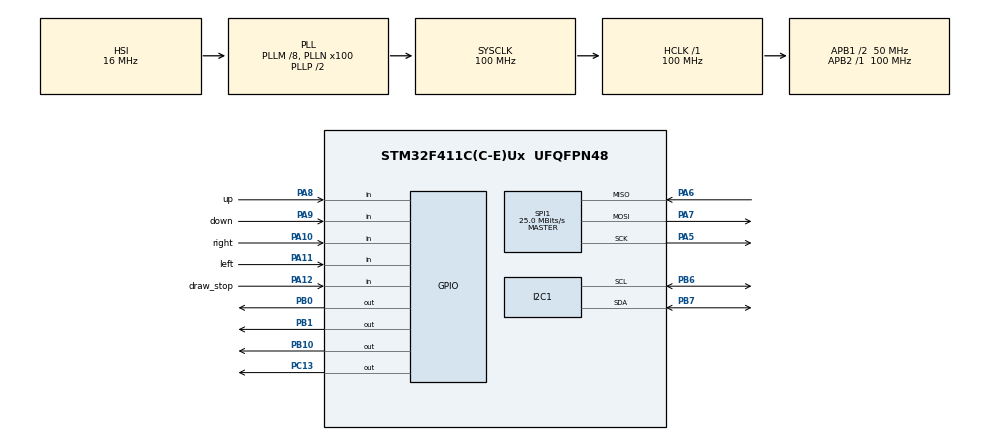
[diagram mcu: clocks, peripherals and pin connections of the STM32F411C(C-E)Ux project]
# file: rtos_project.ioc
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Dma.Request0=SPI1_TX
Dma.SPI1_TX.0.Direction=DMA_MEMORY_TO_PERIPH
Dma.SPI1_TX.0.FIFOMode=DMA_FIFOMODE_DISABLE
Dma.SPI1_TX.0.Instance=DMA2_Stream2
Dma.SPI1_TX.0.MemDataAlignment=DMA_MDATAALIGN_BYTE
Dma.SPI1_TX.0.MemInc=DMA_MINC_ENABLE
Dma.SPI1_TX.0.Mode=DMA_NORMAL
Dma.SPI1_TX.0.PeriphDataAlignment=DMA_PDATAALIGN_BYTE
Dma.SPI1_TX.0.PeriphInc=DMA_PINC_DISABLE
Dma.SPI1_TX.0.Priority=DMA_PRIORITY_LOW
FREERTOS.BinarySemaphores01=disp_semaphore,Dynamic,NULL
FREERTOS.Tasks01=defaultTask,0,128,StartDefaultTask,Default,NULL,Dynamic,NULL,NULL;baca_sht,-2,512,start_baca_sht,Default,NULL,Dynamic,NULL,NULL;display,1,1024,start_display,Default,NULL,Dynamic,NULL,NULL;input_poll,0,256,start_input_poll,Default,NULL,Dynamic,NULL,NULL;game_master,-1,1024,start_game_master,Default,NULL,Dynamic,NULL,NULL
Mcu.Family=STM32F4
Mcu.Name=STM32F411C(C-E)Ux
Mcu.Package=UFQFPN48
NVIC.DMA2_Stream2_IRQn=true\:5\:0\:false\:false\:true\:true\:false\:true\:true
NVIC.PriorityGroup=NVIC_PRIORITYGROUP_4
NVIC.TIM1_UP_TIM10_IRQn=true\:15\:0\:false\:false\:true\:false\:false\:true\:true
NVIC.TimeBase=TIM1_UP_TIM10_IRQn
NVIC.TimeBaseIP=TIM1
PA10.GPIO_Label=right
PA10.GPIO_PuPd=GPIO_PULLDOWN
PA10.Signal=GPIO_Input
PA11.GPIO_Label=left
PA11.GPIO_PuPd=GPIO_PULLDOWN
PA11.Signal=GPIO_Input
PA12.GPIO_Label=draw_stop
PA12.GPIO_PuPd=GPIO_PULLDOWN
PA12.Signal=GPIO_Input
PA13.Mode=Serial_Wire
PA13.Signal=SYS_JTMS-SWDIO
PA14.Mode=Serial_Wire
PA14.Signal=SYS_JTCK-SWCLK
PA5.Mode=Full_Duplex_Master
PA5.Signal=SPI1_SCK
PA6.Mode=Full_Duplex_Master
PA6.Signal=SPI1_MISO
PA7.Mode=Full_Duplex_Master
PA7.Signal=SPI1_MOSI
PA8.GPIO_Label=up
PA8.GPIO_PuPd=GPIO_PULLDOWN
PA8.Signal=GPIO_Input
PA9.GPIO_Label=down
PA9.GPIO_PuPd=GPIO_PULLDOWN
PA9.Signal=GPIO_Input
PB0.Signal=GPIO_Output
PB1.Signal=GPIO_Output
PB10.Signal=GPIO_Output
PB6.Mode=I2C
PB6.Signal=I2C1_SCL
PB7.Mode=I2C
PB7.Signal=I2C1_SDA
PC13-ANTI_TAMP.Signal=GPIO_Output
PC14-OSC32_IN.Mode=LSE-External-Oscillator
PC14-OSC32_IN.Signal=RCC_OSC32_IN
PC15-OSC32_OUT.Mode=LSE-External-Oscillator
PC15-OSC32_OUT.Signal=RCC_OSC32_OUT
PH0\ -\ OSC_IN.Mode=HSE-External-Oscillator
PH0\ -\ OSC_IN.Signal=RCC_OSC_IN
PH1\ -\ OSC_OUT.Mode=HSE-External-Oscillator
PH1\ -\ OSC_OUT.Signal=RCC_OSC_OUT
ProjectManager.HeapSize=0x200
ProjectManager.StackSize=0x400
ProjectManager.TargetToolchain=STM32CubeIDE
RCC.48MHZClocksFreq_Value=50000000
RCC.AHBFreq_Value=100000000
RCC.APB1CLKDivider=RCC_HCLK_DIV2
RCC.APB1Freq_Value=50000000
RCC.APB1TimFreq_Value=100000000
RCC.APB2Freq_Value=100000000
RCC.APB2TimFreq_Value=100000000
RCC.CortexFreq_Value=100000000
RCC.HCLKFreq_Value=100000000
RCC.HSE_VALUE=25000000
RCC.HSI_VALUE=16000000
RCC.PLLM=8
RCC.PLLN=100
RCC.SYSCLKFreq_VALUE=100000000
RCC.SYSCLKSource=RCC_SYSCLKSOURCE_PLLCLK
RCC.VCOOutputFreq_Value=200000000
RTC.Date=22
RTC.Month=RTC_MONTH_SEPTEMBER
RTC.WeekDay=RTC_WEEKDAY_SUNDAY
RTC.Year=24
SPI1.BaudRatePrescaler=SPI_BAUDRATEPRESCALER_4
SPI1.CalculateBaudRate=25.0 MBits/s
SPI1.Direction=SPI_DIRECTION_2LINES
SPI1.Mode=SPI_MODE_MASTER
SPI1.VirtualType=VM_MASTER
VP_FREERTOS_VS_CMSIS_V1.Mode=CMSIS_V1
VP_RTC_VS_RTC_Activate.Mode=RTC_Enabled
VP_RTC_VS_RTC_Calendar.Mode=RTC_Calendar
VP_SYS_VS_tim1.Mode=TIM1
board=custom

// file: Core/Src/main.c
/* USER CODE BEGIN Header */
/**
  ******************************************************************************
  * @file           : main.c
  * @brief          : Main program body
  ******************************************************************************
  * @attention
  *
  * Copyright (c) 2024 STMicroelectronics.
  * All rights reserved.
  *
  * This software is licensed under terms that can be found in the LICENSE file
  * in the root directory of this software component.
  * If no LICENSE file comes with this software, it is provided AS-IS.
  *
  ******************************************************************************
  */
/* USER CODE END Header */
#include "main.h"
#include "cmsis_os.h"

/* USER CODE BEGIN Includes */
#include "stm32f4xx_hal.h"
#include <string.h>
#include <stdarg.h>
#include <stdio.h>
#include <stdbool.h>
#include <stdlib.h>
#include "ili9341.h"
#include "ili9341_touch.h"
#include "fonts.h"
#include "testimg.h"
#include "sht2x_for_stm32_hal.h"
/* USER CODE END Includes */

/* USER CODE BEGIN PD */
#define INCREMENT 1
#define PADDLE_WIDTH 5
#define PADDLE_HEIGHT 30
#define PADDLE_SPEED 4
#define BALL_SIZE 3
#define BALL_VELY 5
#define BALL_VELX 5
/* USER CODE END PD */

I2C_HandleTypeDef hi2c1;

RTC_HandleTypeDef hrtc;

SPI_HandleTypeDef hspi1;
DMA_HandleTypeDef hdma_spi1_tx;

osThreadId defaultTaskHandle;
osThreadId baca_shtHandle;
osThreadId displayHandle;
osThreadId input_pollHandle;
osThreadId game_masterHandle;
osSemaphoreId disp_semaphoreHandle;
/* USER CODE BEGIN PV */
static float temp=0;
static float hum;
char str1[40];
char str2[40];
char date[150];
char score_left[10];
char score_right[10];
int scoreL;
int scoreR;
float buffer[10]; // Moving Average Filter
float buffer_hum[10];
float filtered_temp;
float filtered_hum;
int x,y;
int oldx,oldy;
int ouserx,ousery;
int obotx,oboty;
int random_number;
//bool isDrawing;
bool playerEnable;

typedef struct {
	int x;
	int y;
	int width;
	int height;
	int speed;
} paddle;

typedef struct {
	int x;
	int y;
	int velx;
	int vely;
	int rad;
} ball;

paddle user;
paddle bot;
ball bola;

// GAMBAR PETIR
const uint16_t test_img_50x50[][50] = {
{0x0000,0x0000,0x0000,0x0000,0x0000,0x0000,0x0000,0x0000,0x0000,0x0000,0x0000,0x0000,0x0000,0x0000,0x0000,0x0000,0x0000,0x0000,0x0000,0x0000,0x0000,0x0000,0x0000,0x0000,0x0000,0x0000,0x0000,0x0000,0x0000,0x0000,0x0000,0x0000,0x0000,0x0000,0x0000,0x0000,0x0000,0x0000,0x0000,0x0000,0x0000,0x0000,0x0000,0x0000,0x0000,0x0000,0x0000,0x0000,0x0000,0x0000,},
{0x0000,0x0000,0x0000,0x0000,0x0000,0x0000,0x0000,0x0000,0x0000,0x0000,0x0000,0x0000,0x0000,0x0000,0x0000,0x0000,0x0000,0x0000,0x0000,0x0000,0x0000,0x0000,0x0000,0x0000,0x0000,0x0000,0x0000,0x0000,0x0000,0x0000,0x0000,0x0000,0x0000,0x0000,0x0000,0x0000,0x0000,0x0000,0x0000,0x0000,0x0000,0x0000,0x0000,0x0000,0x0000,0x0000,0x0000,0x0000,0x0000,0x0000,},
{0x0000,0x0000,0x0000,0x0000,0x0000,0x0000,0x0000,0x0000,0x0000,0x0000,0x0000,0x0000,0x0000,0x0000,0x0000,0x0000,0x0000,0x0000,0x0000,0x0000,0x0000,0x0000,0x0000,0x0000,0x0000,0x0000,0x0000,0x0000,0x0000,0x0000,0x0000,0x0000,0x0000,0x0000,0x0000,0x0000,0x0000,0x0000,0x0000,0x0000,0x0000,0x0000,0x0000,0x0000,0x0000,0x0000,0x0000,0x0000,0x0000,0x0000,},
{0x0000,0x0000,0x0000,0x0000,0x0000,0x0000,0x0000,0x0000,0x0000,0x0000,0x0000,0x0000,0x0000,0x0000,0x0000,0x0000,0x0000,0x0000,0x0000,0x0000,0x0000,0x4529,0xEB5A,0xE739,0x4108,0x0000,0x0000,0x0000,0x0000,0x0000,0x0000,0x0000,0x0000,0x0000,0x0000,0x0000,0x0000,0x0000,0x0000,0x0000,0x0000,0x0000,0x0000,0x0000,0x0000,0x0000,0x0000,0x0000,0x0000,0x0000,},
{0x0000,0x0000,0x0000,0x0000,0x0000,0x0000,0x0000,0x0000,0x0000,0x0000,0x0000,0x0000,0x0000,0x0000,0x0000,0x0000,0x0000,0x0000,0x0000,0x0000,0x4529,0x38C6,0x9EF7,0x3CE7,0xEB5A,0x4108,0x0000,0x0000,0x0000,0x0000,0x0000,0x0000,0x0000,0x0000,0x0000,0x0000,0x0000,0x0000,0x0000,0x0000,0x0000,0x0000,0x0000,0x0000,0x0000,0x0000,0x0000,0x0000,0x0000,0x0000,},
{0x0000,0x0000,0x0000,0x0000,0x0000,0x0000,0x0000,0x0000,0x0000,0x0000,0x0000,0x0000,0x0000,0x0000,0x0000,0x0000,0x0000,0x0000,0x0000,0x0000,0xEF7B,0xFFFF,0xFFFF,0xFFFF,0xD7BD,0x0421,0x0000,0x0000,0x0000,0x0000,0x0000,0x0000,0x0000,0x0000,0x0000,0x0000,0x0000,0x0000,0x0000,0x0000,0x0000,0x0000,0x0000,0x0000,0x0000,0x0000,0x0000,0x0000,0x0000,0x0000,},
{0x0000,0x0000,0x0000,0x0000,0x0000,0x0000,0x0000,0x0000,0x0000,0x0000,0x0000,0x0000,0x0000,0x0000,0x0000,0x0000,0x0000,0x0000,0x0000,0x0000,0x18C6,0xFFFF,0xFFFF,0xFFFF,0xBAD6,0x2421,0x0000,0x0000,0x0000,0x0000,0x0000,0x0000,0x0000,0x0000,0x0000,0x0000,0x0000,0x0000,0x0000,0x0000,0x0000,0x0000,0x0000,0x0000,0x0000,0x0000,0x0000,0x0000,0x0000,0x0000,},
{0x0000,0x0000,0x0000,0x0000,0x0000,0x0000,0x0000,0x0000,0x0000,0x0000,0x0000,0x0000,0x0000,0x0000,0x0000,0x0000,0x0000,0x0000,0x0000,0x694A,0xDFFF,0xFFFF,0xFFFF,0xFFFF,0x38C6,0x6108,0x0000,0x0000,0x0000,0x0000,0x0000,0x0000,0x0000,0x0000,0x0000,0x0000,0x0000,0x0000,0x0000,0x0000,0x0000,0x0000,0x0000,0x0000,0x0000,0x0000,0x0000,0x0000,0x0000,0x0000,},
{0x0000,0x0000,0x0000,0x0000,0x0000,0x0000,0x0000,0x0000,0x0000,0x0000,0x0000,0x0000,0x0000,0x0000,0x0000,0x0000,0x0000,0x0000,0x0000,0xF7BD,0xFFFF,0xFFFF,0xFFFF,0xFFFF,0xEF7B,0x0000,0x0000,0x0000,0x0000,0x0000,0x0000,0x0000,0x0000,0x0000,0x0000,0x0000,0x0000,0x0000,0x0000,0x0000,0x0000,0x0000,0x0000,0x0000,0x0000,0x0000,0x0000,0x0000,0x0000,0x0000,},
{0x0000,0x0000,0x0000,0x0000,0x0000,0x0000,0x0000,0x0000,0x0000,0x0000,0x0000,0x0000,0x0000,0x0000,0x0000,0x0000,0x0000,0x0000,0xAA52,0xBEF7,0xFFFF,0xFFFF,0xFFFF,0x9EF7,0xA631,0x0000,0x0000,0x0000,0x0000,0x0000,0x0000,0x0000,0x0000,0x0000,0x0000,0x0000,0x0000,0x0000,0x0000,0x0000,0x0000,0x0000,0x0000,0x0000,0x0000,0x0000,0x0000,0x0000,0x0000,0x0000,},
{0x0000,0x0000,0x0000,0x0000,0x0000,0x0000,0x0000,0x0000,0x0000,0x0000,0x0000,0x0000,0x0000,0x0000,0x0000,0x0000,0x0000,0x0421,0xDBDE,0xFFFF,0xFFFF,0xFFFF,0xFFFF,0xB6B5,0x6108,0x0000,0x0000,0x0000,0x0000,0x0000,0x0000,0x0000,0x0000,0x0000,0x0000,0x0000,0x0000,0x0000,0x0000,0x0000,0x0000,0x0000,0x0000,0x0000,0x0000,0x0000,0x0000,0x0000,0x0000,0x0000,},
{0x0000,0x0000,0x0000,0x0000,0x0000,0x0000,0x0000,0x0000,0x0000,0x0000,0x0000,0x0000,0x0000,0x0000,0x0000,0x0000,0x0000,0xD39C,0xFFFF,0xFFFF,0xFFFF,0xFFFF,0x7DEF,0x2842,0x0000,0x0000,0x0000,0x0000,0x0000,0x0000,0x0000,0x0000,0x0000,0x0000,0x0000,0x0000,0x0000,0x0000,0x0000,0x0000,0x0000,0x0000,0x0000,0x0000,0x0000,0x0000,0x0000,0x0000,0x0000,0x0000,},
{0x0000,0x0000,0x0000,0x0000,0x0000,0x0000,0x0000,0x0000,0x0000,0x0000,0x0000,0x0000,0x0000,0x0000,0x0000,0x0000,0xE739,0x9EF7,0xFFFF,0xFFFF,0xFFFF,0xFFFF,0xEF7B,0x0000,0x0000,0x0000,0x0000,0x0000,0x0000,0x0000,0x0000,0x0000,0x0000,0x0000,0x0000,0x0000,0x0000,0x0000,0x0000,0x0000,0x0000,0x0000,0x0000,0x0000,0x0000,0x0000,0x0000,0x0000,0x0000,0x0000,},
{0x0000,0x0000,0x0000,0x0000,0x0000,0x0000,0x0000,0x0000,0x0000,0x0000,0x0000,0x0000,0x0000,0x0000,0x0000,0x0000,0xF39C,0xFFFF,0xFFFF,0xFFFF,0xFFFF,0x3CE7,0x0421,0x0000,0x0000,0x0000,0x0000,0x0000,0x0000,0x0000,0x0000,0x0000,0x0000,0x0000,0x0000,0x0000,0x0000,0x0000,0x0000,0x0000,0x0000,0x0000,0x0000,0x0000,0x0000,0x0000,0x0000,0x0000,0x0000,0x0000,},
{0x0000,0x0000,0x0000,0x0000,0x0000,0x0000,0x0000,0x0000,0x0000,0x0000,0x0000,0x0000,0x0000,0x0000,0x0000,0x4529,0x3CE7,0xFFFF,0xFFFF,0xFFFF,0xFFFF,0x718C,0x0000,0x0000,0x0000,0x0000,0x0000,0x0000,0x0000,0x0000,0x0000,0x0000,0x0000,0x0000,0x0000,0x0000,0x0000,0x0000,0x0000,0x0000,0x0000,0x0000,0x0000,0x0000,0x0000,0x0000,0x0000,0x0000,0x0000,0x0000,},
{0x0000,0x0000,0x0000,0x0000,0x0000,0x0000,0x0000,0x0000,0x0000,0x0000,0x0000,0x0000,0x0000,0x0000,0x0000,0x518C,0xFFFF,0xFFFF,0xFFFF,0xFFFF,0x3CE7,0x0421,0x0000,0x0000,0x0000,0x0000,0x0000,0x0000,0x0000,0x0000,0x0000,0x0000,0x0000,0x0000,0x0000,0x0000,0x0000,0x0000,0x0000,0x0000,0x0000,0x0000,0x0000,0x0000,0x0000,0x0000,0x0000,0x0000,0x0000,0x0000,},
{0x0000,0x0000,0x0000,0x0000,0x0000,0x0000,0x0000,0x0000,0x0000,0x0000,0x0000,0x0000,0x0000,0x0000,0x4529,0x3CE7,0xFFFF,0xFFFF,0xFFFF,0xFFFF,0x9294,0x0000,0x0000,0x0000,0x0000,0x0000,0x0000,0x0000,0x0000,0x0000,0x0000,0x0000,0x0000,0x0000,0x0000,0x0000,0x0000,0x0000,0x0000,0x0000,0x0000,0x0000,0x0000,0x0000,0x0000,0x0000,0x0000,0x0000,0x0000,0x0000,},
{0x0000,0x0000,0x0000,0x0000,0x0000,0x0000,0x0000,0x0000,0x0000,0x0000,0x0000,0x0000,0x0000,0x0000,0xF39C,0xFFFF,0xFFFF,0xFFFF,0xFFFF,0x1CE7,0x0421,0x0000,0x0000,0x0000,0x0000,0x0000,0x0000,0x0000,0x0000,0x0000,0x0000,0x0000,0x0000,0x0000,0x0000,0x0000,0x0000,0x0000,0x0000,0x0000,0x0000,0x0000,0x0000,0x0000,0x0000,0x0000,0x0000,0x0000,0x0000,0x0000,},
{0x0000,0x0000,0x0000,0x0000,0x0000,0x0000,0x0000,0x0000,0x0000,0x0000,0x0000,0x0000,0x0000,0xE739,0xBEF7,0xFFFF,0xFFFF,0xFFFF,0xFFFF,0x0C63,0x0000,0x0000,0x0000,0x0000,0x0000,0x0000,0x0000,0x0000,0x0000,0x0000,0x0000,0x0000,0x0000,0x0000,0x0000,0x0000,0x0000,0x0000,0x0000,0x0000,0x0000,0x0000,0x0000,0x0000,0x0000,0x0000,0x0000,0x0000,0x0000,0x0000,},
{0x0000,0x0000,0x0000,0x0000,0x0000,0x0000,0x0000,0x0000,0x0000,0x0000,0x0000,0x0000,0x0000,0x75AD,0xFFFF,0xFFFF,0xFFFF,0xFFFF,0xB6B5,0x0000,0x0000,0x0000,0x0000,0x0000,0x0000,0x0000,0x0000,0x0000,0x0000,0x0000,0x0000,0x0000,0x0000,0x0000,0x0000,0x0000,0x0000,0x0000,0x0000,0x0000,0x0000,0x0000,0x0000,0x0000,0x0000,0x0000,0x0000,0x0000,0x0000,0x0000,},
{0x0000,0x0000,0x0000,0x0000,0x0000,0x0000,0x0000,0x0000,0x0000,0x0000,0x0000,0x0000,0xE739,0xBEF7,0xFFFF,0xFFFF,0xFFFF,0xBEF7,0xE739,0x0000,0x0000,0x0000,0x0000,0x0000,0x0000,0x0000,0x0000,0x0000,0x0000,0x0000,0x0000,0x0000,0x0000,0x0000,0x0000,0x0000,0x0000,0x0000,0x0000,0x0000,0x0000,0x0000,0x0000,0x0000,0x0000,0x0000,0x0000,0x0000,0x0000,0x0000,},
{0x0000,0x0000,0x0000,0x0000,0x0000,0x0000,0x0000,0x0000,0x0000,0x0000,0x0000,0x0000,0x34A5,0xFFFF,0xFFFF,0xFFFF,0xFFFF,0xB294,0x0000,0x0000,0x0000,0x0000,0x0000,0x0000,0x0000,0x0000,0x0000,0x0000,0x0000,0x0000,0x0000,0x0000,0x0000,0x0000,0x0000,0x0000,0x0000,0x0000,0x0000,0x0000,0x0000,0x0000,0x0000,0x0000,0x0000,0x0000,0x0000,0x0000,0x0000,0x0000,},
{0x0000,0x0000,0x0000,0x0000,0x0000,0x0000,0x0000,0x0000,0x0000,0x0000,0x0000,0x6108,0xFBDE,0xFFFF,0xFFFF,0xFFFF,0x9EF7,0xA631,0x0000,0x0000,0x0000,0x0000,0x0000,0x0000,0x0000,0x0000,0x6108,0x2421,0x6529,0x6529,0xE739,0x0C63,0xCB5A,0x0421,0x0000,0x0000,0x0000,0x0000,0x0000,0x0000,0x0000,0x0000,0x0000,0x0000,0x0000,0x0000,0x0000,0x0000,0x0000,0x0000,},
{0x0000,0x0000,0x0000,0x0000,0x0000,0x0000,0x0000,0x0000,0x0000,0x0000,0x0000,0x14A5,0xFFFF,0xFFFF,0xFFFF,0xFFFF,0xFBDE,0x8E73,0x6D6B,0x6D6B,0x6D6B,0xCF7B,0xB294,0xF39C,0x34A5,0xB6B5,0x59CE,0x9AD6,0xFBDE,0x1CE7,0x9EF7,0xDFFF,0x9EF7,0x75AD,0x0421,0x0000,0x0000,0x0000,0x0000,0x0000,0x0000,0x0000,0x0000,0x0000,0x0000,0x0000,0x0000,0x0000,0x0000,0x0000,},
{0x0000,0x0000,0x0000,0x0000,0x0000,0x0000,0x0000,0x0000,0x0000,0x0000,0x4D6B,0xFFFF,0xFFFF,0xFFFF,0xFFFF,0xFFFF,0xDFFF,0xDFFF,0xDFFF,0xDFFF,0xDFFF,0xFFFF,0xFFFF,0xFFFF,0xFFFF,0xFFFF,0xFFFF,0xFFFF,0xFFFF,0xFFFF,0xFFFF,0xFFFF,0xFFFF,0xFFFF,0x2C63,0x0000,0x0000,0x0000,0x0000,0x0000,0x0000,0x0000,0x0000,0x0000,0x0000,0x0000,0x0000,0x0000,0x0000,0x0000,},
{0x0000,0x0000,0x0000,0x0000,0x0000,0x0000,0x0000,0x0000,0x0000,0x6108,0xBAD6,0xFFFF,0xFFFF,0xFFFF,0xFFFF,0xFFFF,0xFFFF,0xFFFF,0xFFFF,0xFFFF,0xFFFF,0xFFFF,0xFFFF,0xFFFF,0xFFFF,0xFFFF,0xFFFF,0xFFFF,0xFFFF,0xFFFF,0xFFFF,0xFFFF,0xFFFF,0xFFFF,0xAE73,0x0000,0x0000,0x0000,0x0000,0x0000,0x0000,0x0000,0x0000,0x0000,0x0000,0x0000,0x0000,0x0000,0x0000,0x0000,},
{0x0000,0x0000,0x0000,0x0000,0x0000,0x0000,0x0000,0x0000,0x0000,0xA210,0x9AD6,0xFFFF,0xFFFF,0xFFFF,0xFFFF,0xFFFF,0xFFFF,0xFFFF,0xFFFF,0xFFFF,0xFFFF,0xFFFF,0xFFFF,0xFFFF,0xFFFF,0xFFFF,0xFFFF,0xFFFF,0xFFFF,0xFFFF,0xFFFF,0xFFFF,0xFFFF,0x9EF7,0xE739,0x0000,0x0000,0x0000,0x0000,0x0000,0x0000,0x0000,0x0000,0x0000,0x0000,0x0000,0x0000,0x0000,0x0000,0x0000,},
{0x0000,0x0000,0x0000,0x0000,0x0000,0x0000,0x0000,0x0000,0x0000,0x4108,0xAE73,0xDFFF,0xFFFF,0xFFFF,0xDFFF,0xBEF7,0xDFFF,0xDFFF,0xDFFF,0xDFFF,0xBEF7,0x9EF7,0x7DEF,0xFBDE,0xBAD6,0x59CE,0xB6B5,0x96B5,0xBEF7,0xFFFF,0xFFFF,0xFFFF,0xFFFF,0x34A5,0x6108,0x0000,0x0000,0x0000,0x0000,0x0000,0x0000,0x0000,0x0000,0x0000,0x0000,0x0000,0x0000,0x0000,0x0000,0x0000,},
{0x0000,0x0000,0x0000,0x0000,0x0000,0x0000,0x0000,0x0000,0x0000,0x0000,0x4108,0x2C63,0x34A5,0xEF7B,0x0C63,0x6D6B,0x6D6B,0x6D6B,0x6D6B,0x6D6B,0x6D6B,0x0C63,0x0842,0x8631,0x2421,0x6108,0x0000,0xF39C,0xFFFF,0xFFFF,0xFFFF,0xFFFF,0x3CE7,0x4529,0x0000,0x0000,0x0000,0x0000,0x0000,0x0000,0x0000,0x0000,0x0000,0x0000,0x0000,0x0000,0x0000,0x0000,0x0000,0x0000,},
{0x0000,0x0000,0x0000,0x0000,0x0000,0x0000,0x0000,0x0000,0x0000,0x0000,0x0000,0x0000,0x0000,0x0000,0x0000,0x0000,0x0000,0x0000,0x0000,0x0000,0x0000,0x0000,0x0000,0x0000,0x0000,0x0000,0x4D6B,0xDFFF,0xFFFF,0xFFFF,0xFFFF,0xFFFF,0x0C63,0x0000,0x0000,0x0000,0x0000,0x0000,0x0000,0x0000,0x0000,0x0000,0x0000,0x0000,0x0000,0x0000,0x0000,0x0000,0x0000,0x0000,},
{0x0000,0x0000,0x0000,0x0000,0x0000,0x0000,0x0000,0x0000,0x0000,0x0000,0x0000,0x0000,0x0000,0x0000,0x0000,0x0000,0x0000,0x0000,0x0000,0x0000,0x0000,0x0000,0x0000,0x0000,0x0000,0xE739,0x7DEF,0xFFFF,0xFFFF,0xFFFF,0xFFFF,0xB6B5,0x0000,0x0000,0x0000,0x0000,0x0000,0x0000,0x0000,0x0000,0x0000,0x0000,0x0000,0x0000,0x0000,0x0000,0x0000,0x0000,0x0000,0x0000,},
{0x0000,0x0000,0x0000,0x0000,0x0000,0x0000,0x0000,0x0000,0x0000,0x0000,0x0000,0x0000,0x0000,0x0000,0x0000,0x0000,0x0000,0x0000,0x0000,0x0000,0x0000,0x0000,0x0000,0x0000,0x0000,0xF39C,0xFFFF,0xFFFF,0xFFFF,0xFFFF,0x7DEF,0xE739,0x0000,0x0000,0x0000,0x0000,0x0000,0x0000,0x0000,0x0000,0x0000,0x0000,0x0000,0x0000,0x0000,0x0000,0x0000,0x0000,0x0000,0x0000,},
{0x0000,0x0000,0x0000,0x0000,0x0000,0x0000,0x0000,0x0000,0x0000,0x0000,0x0000,0x0000,0x0000,0x0000,0x0000,0x0000,0x0000,0x0000,0x0000,0x0000,0x0000,0x0000,0x0000,0x0000,0x6108,0xBAD6,0xFFFF,0xFFFF,0xFFFF,0xDFFF,0xEF7B,0x0000,0x0000,0x0000,0x0000,0x0000,0x0000,0x0000,0x0000,0x0000,0x0000,0x0000,0x0000,0x0000,0x0000,0x0000,0x0000,0x0000,0x0000,0x0000,},
{0x0000,0x0000,0x0000,0x0000,0x0000,0x0000,0x0000,0x0000,0x0000,0x0000,0x0000,0x0000,0x0000,0x0000,0x0000,0x0000,0x0000,0x0000,0x0000,0x0000,0x0000,0x0000,0x0000,0x0000,0x4D6B,0xFFFF,0xFFFF,0xFFFF,0xFFFF,0x1CE7,0x0421,0x0000,0x0000,0x0000,0x0000,0x0000,0x0000,0x0000,0x0000,0x0000,0x0000,0x0000,0x0000,0x0000,0x0000,0x0000,0x0000,0x0000,0x0000,0x0000,},
{0x0000,0x0000,0x0000,0x0000,0x0000,0x0000,0x0000,0x0000,0x0000,0x0000,0x0000,0x0000,0x0000,0x0000,0x0000,0x0000,0x0000,0x0000,0x0000,0x0000,0x0000,0x0000,0x0000,0x6108,0xBAD6,0xFFFF,0xFFFF,0xFFFF,0xFFFF,0x1084,0x0000,0x0000,0x0000,0x0000,0x0000,0x0000,0x0000,0x0000,0x0000,0x0000,0x0000,0x0000,0x0000,0x0000,0x0000,0x0000,0x0000,0x0000,0x0000,0x0000,},
{0x0000,0x0000,0x0000,0x0000,0x0000,0x0000,0x0000,0x0000,0x0000,0x0000,0x0000,0x0000,0x0000,0x0000,0x0000,0x0000,0x0000,0x0000,0x0000,0x0000,0x0000,0x0000,0x0000,0x718C,0xFFFF,0xFFFF,0xFFFF,0xFFFF,0x1CE7,0x0421,0x0000,0x0000,0x0000,0x0000,0x0000,0x0000,0x0000,0x0000,0x0000,0x0000,0x0000,0x0000,0x0000,0x0000,0x0000,0x0000,0x0000,0x0000,0x0000,0x0000,},
{0x0000,0x0000,0x0000,0x0000,0x0000,0x0000,0x0000,0x0000,0x0000,0x0000,0x0000,0x0000,0x0000,0x0000,0x0000,0x0000,0x0000,0x0000,0x0000,0x0000,0x0000,0x0000,0xCB5A,0xFFFF,0xFFFF,0xFFFF,0xFFFF,0xFFFF,0xCF7B,0x0000,0x0000,0x0000,0x0000,0x0000,0x0000,0x0000,0x0000,0x0000,0x0000,0x0000,0x0000,0x0000,0x0000,0x0000,0x0000,0x0000,0x0000,0x0000,0x0000,0x0000,},
{0x0000,0x0000,0x0000,0x0000,0x0000,0x0000,0x0000,0x0000,0x0000,0x0000,0x0000,0x0000,0x0000,0x0000,0x0000,0x0000,0x0000,0x0000,0x0000,0x0000,0x0000,0x0421,0xFBDE,0xFFFF,0xFFFF,0xFFFF,0xFFFF,0x3CE7,0x0421,0x0000,0x0000,0x0000,0x0000,0x0000,0x0000,0x0000,0x0000,0x0000,0x0000,0x0000,0x0000,0x0000,0x0000,0x0000,0x0000,0x0000,0x0000,0x0000,0x0000,0x0000,},
{0x0000,0x0000,0x0000,0x0000,0x0000,0x0000,0x0000,0x0000,0x0000,0x0000,0x0000,0x0000,0x0000,0x0000,0x0000,0x0000,0x0000,0x0000,0x0000,0x0000,0x0000,0x718C,0xFFFF,0xFFFF,0xFFFF,0xFFFF,0xFFFF,0x4D6B,0x0000,0x0000,0x0000,0x0000,0x0000,0x0000,0x0000,0x0000,0x0000,0x0000,0x0000,0x0000,0x0000,0x0000,0x0000,0x0000,0x0000,0x0000,0x0000,0x0000,0x0000,0x0000,},
{0x0000,0x0000,0x0000,0x0000,0x0000,0x0000,0x0000,0x0000,0x0000,0x0000,0x0000,0x0000,0x0000,0x0000,0x0000,0x0000,0x0000,0x0000,0x0000,0x0000,0x4529,0x3CE7,0xFFFF,0xFFFF,0xFFFF,0xFFFF,0x55AD,0x6108,0x0000,0x0000,0x0000,0x0000,0x0000,0x0000,0x0000,0x0000,0x0000,0x0000,0x0000,0x0000,0x0000,0x0000,0x0000,0x0000,0x0000,0x0000,0x0000,0x0000,0x0000,0x0000,},
{0x0000,0x0000,0x0000,0x0000,0x0000,0x0000,0x0000,0x0000,0x0000,0x0000,0x0000,0x0000,0x0000,0x0000,0x0000,0x0000,0x0000,0x0000,0x0000,0x0000,0x9294,0xFFFF,0xFFFF,0xFFFF,0xFFFF,0x1CE7,0x4529,0x0000,0x0000,0x0000,0x0000,0x0000,0x0000,0x0000,0x0000,0x0000,0x0000,0x0000,0x0000,0x0000,0x0000,0x0000,0x0000,0x0000,0x0000,0x0000,0x0000,0x0000,0x0000,0x0000,},
{0x0000,0x0000,0x0000,0x0000,0x0000,0x0000,0x0000,0x0000,0x0000,0x0000,0x0000,0x0000,0x0000,0x0000,0x0000,0x0000,0x0000,0x0000,0x0000,0x0421,0xFBDE,0xFFFF,0xFFFF,0xFFFF,0xFFFF,0xCF7B,0x0000,0x0000,0x0000,0x0000,0x0000,0x0000,0x0000,0x0000,0x0000,0x0000,0x0000,0x0000,0x0000,0x0000,0x0000,0x0000,0x0000,0x0000,0x0000,0x0000,0x0000,0x0000,0x0000,0x0000,},
{0x0000,0x0000,0x0000,0x0000,0x0000,0x0000,0x0000,0x0000,0x0000,0x0000,0x0000,0x0000,0x0000,0x0000,0x0000,0x0000,0x0000,0x0000,0x0000,0x0C63,0xFFFF,0xFFFF,0xFFFF,0xFFFF,0xFBDE,0x0421,0x0000,0x0000,0x0000,0x0000,0x0000,0x0000,0x0000,0x0000,0x0000,0x0000,0x0000,0x0000,0x0000,0x0000,0x0000,0x0000,0x0000,0x0000,0x0000,0x0000,0x0000,0x0000,0x0000,0x0000,},
{0x0000,0x0000,0x0000,0x0000,0x0000,0x0000,0x0000,0x0000,0x0000,0x0000,0x0000,0x0000,0x0000,0x0000,0x0000,0x0000,0x0000,0x0000,0x0000,0x0C63,0xFFFF,0xFFFF,0xFFFF,0xFFFF,0xCB5A,0x0000,0x0000,0x0000,0x0000,0x0000,0x0000,0x0000,0x0000,0x0000,0x0000,0x0000,0x0000,0x0000,0x0000,0x0000,0x0000,0x0000,0x0000,0x0000,0x0000,0x0000,0x0000,0x0000,0x0000,0x0000,},
{0x0000,0x0000,0x0000,0x0000,0x0000,0x0000,0x0000,0x0000,0x0000,0x0000,0x0000,0x0000,0x0000,0x0000,0x0000,0x0000,0x0000,0x0000,0x0000,0x0421,0x14A5,0x9AD6,0x9AD6,0xCB5A,0x0000,0x0000,0x0000,0x0000,0x0000,0x0000,0x0000,0x0000,0x0000,0x0000,0x0000,0x0000,0x0000,0x0000,0x0000,0x0000,0x0000,0x0000,0x0000,0x0000,0x0000,0x0000,0x0000,0x0000,0x0000,0x0000,},
{0x0000,0x0000,0x0000,0x0000,0x0000,0x0000,0x0000,0x0000,0x0000,0x0000,0x0000,0x0000,0x0000,0x0000,0x0000,0x0000,0x0000,0x0000,0x0000,0x0000,0x0421,0x0842,0x0421,0x0000,0x0000,0x0000,0x0000,0x0000,0x0000,0x0000,0x0000,0x0000,0x0000,0x0000,0x0000,0x0000,0x0000,0x0000,0x0000,0x0000,0x0000,0x0000,0x0000,0x0000,0x0000,0x0000,0x0000,0x0000,0x0000,0x0000,},
{0x0000,0x0000,0x0000,0x0000,0x0000,0x0000,0x0000,0x0000,0x0000,0x0000,0x0000,0x0000,0x0000,0x0000,0x0000,0x0000,0x0000,0x0000,0x0000,0x0000,0x0000,0x0000,0x0000,0x0000,0x0000,0x0000,0x0000,0x0000,0x0000,0x0000,0x0000,0x0000,0x0000,0x0000,0x0000,0x0000,0x0000,0x0000,0x0000,0x0000,0x0000,0x0000,0x0000,0x0000,0x0000,0x0000,0x0000,0x0000,0x0000,0x0000,},
{0x0000,0x0000,0x0000,0x0000,0x0000,0x0000,0x0000,0x0000,0x0000,0x0000,0x0000,0x0000,0x0000,0x0000,0x0000,0x0000,0x0000,0x0000,0x0000,0x0000,0x0000,0x0000,0x0000,0x0000,0x0000,0x0000,0x0000,0x0000,0x0000,0x0000,0x0000,0x0000,0x0000,0x0000,0x0000,0x0000,0x0000,0x0000,0x0000,0x0000,0x0000,0x0000,0x0000,0x0000,0x0000,0x0000,0x0000,0x0000,0x0000,0x0000,},
{0x0000,0x0000,0x0000,0x0000,0x0000,0x0000,0x0000,0x0000,0x0000,0x0000,0x0000,0x0000,0x0000,0x0000,0x0000,0x0000,0x0000,0x0000,0x0000,0x0000,0x0000,0x0000,0x0000,0x0000,0x0000,0x0000,0x0000,0x0000,0x0000,0x0000,0x0000,0x0000,0x0000,0x0000,0x0000,0x0000,0x0000,0x0000,0x0000,0x0000,0x0000,0x0000,0x0000,0x0000,0x0000,0x0000,0x0000,0x0000,0x0000,0x0000,},
{0x0000,0x0000,0x0000,0x0000,0x0000,0x0000,0x0000,0x0000,0x0000,0x0000,0x0000,0x0000,0x0000,0x0000,0x0000,0x0000,0x0000,0x0000,0x0000,0x0000,0x0000,0x0000,0x0000,0x0000,0x0000,0x0000,0x0000,0x0000,0x0000,0x0000,0x0000,0x0000,0x0000,0x0000,0x0000,0x0000,0x0000,0x0000,0x0000,0x0000,0x0000,0x0000,0x0000,0x0000,0x0000,0x0000,0x0000,0x0000,0x0000,0xA210,},
};

// Gambar SOST
const uint16_t gambar_sost[][50] = {
{0x0000,0x0000,0x0000,0x0000,0x0000,0x0000,0x0000,0x0000,0x0000,0x0000,0x0000,0x0000,0x0000,0x0000,0x0000,0x0000,0x0000,0x0000,0x0000,0x0000,0x0000,0x0000,0x0000,0x0000,0x0000,0x0000,0x0000,0x0000,0x0000,0x0000,0x0000,0x0000,0x0000,0x0000,0x0000,0x0000,0x0000,0x0000,0x0000,0x0000,0x0000,0x0000,0x0000,0x0000,0x0000,0x0000,0x0000,0x0000,0x0000,0x0000,},
{0x0000,0x0000,0x0000,0x0000,0x0000,0x0000,0x0000,0x0000,0x0000,0x0000,0x6108,0xA631,0xAE73,0x9294,0x718C,0x9294,0xAE73,0xA631,0x6108,0x0000,0x0000,0x0000,0x0000,0x0000,0x0000,0x0000,0x0000,0x0000,0x0000,0x0000,0x0000,0x0000,0x0000,0x0000,0x0000,0x0000,0x0000,0x0000,0x0000,0x0000,0x0000,0x0000,0x0000,0x0000,0x0000,0x0000,0x0000,0x0000,0x0000,0x0000,},
{0x0000,0x0000,0x0000,0x0000,0x0000,0x0000,0x0000,0x0000,0x0000,0x6108,0xCF7B,0x1CE7,0xDFFF,0xFFFF,0xFFFF,0xFFFF,0xDFFF,0x3CE7,0x34A5,0x0C63,0x0421,0x0000,0x0000,0x0000,0x0000,0x0000,0x0000,0x0000,0x0000,0x0000,0x0000,0x0000,0x0000,0x0000,0x0000,0x0421,0xCB5A,0x6D6B,0x6D6B,0xCB5A,0x0421,0x0000,0x0000,0x0000,0x0000,0x0000,0x0000,0x0000,0x0000,0x0000,},
{0x0000,0x0000,0x0000,0x0000,0x0000,0x0000,0x0000,0x0000,0x0000,0x518C,0xFFFF,0xFFFF,0xFFFF,0xFFFF,0xFFFF,0xFFFF,0xFFFF,0xFFFF,0xFFFF,0xDFFF,0xFBDE,0x8A52,0x0000,0x0000,0x0000,0x0000,0x0000,0x0000,0x0000,0x0000,0x0000,0x0000,0x0000,0x6108,0x694A,0x9AD6,0xBEF7,0xFFFF,0xFFFF,0xDFFF,0xFBDE,0xCB5A,0x0000,0x0000,0x0000,0x0000,0x0000,0x0000,0x0000,0x0000,},
{0x0000,0x0000,0x0000,0x0000,0x0000,0x0000,0x0000,0x0000,0xCF7B,0xFFFF,0xFFFF,0xFFFF,0xFFFF,0xFFFF,0xFFFF,0xFFFF,0xFFFF,0xFFFF,0xFFFF,0xFFFF,0xFFFF,0x5DEF,0xA631,0x0000,0x0000,0x0000,0x0000,0x0000,0x0000,0x0000,0x0000,0x0000,0x4529,0xD39C,0x7DEF,0xFFFF,0xFFFF,0xFFFF,0xFFFF,0xFFFF,0xFFFF,0xFFFF,0xEB5A,0x0000,0x0000,0x0000,0x0000,0x0000,0x0000,0x0000,},
{0x0000,0x0000,0x0000,0x0000,0x0000,0x0000,0x0000,0x0C63,0xDFFF,0xFFFF,0xFFFF,0xFFFF,0xFFFF,0xFFFF,0xFFFF,0xFFFF,0xFFFF,0xFFFF,0xFFFF,0xFFFF,0xFFFF,0xFFFF,0xCF7B,0x0000,0x0000,0x0000,0x0000,0x0000,0x0000,0x0000,0x0000,0xE739,0x9AD6,0xFFFF,0xFFFF,0xFFFF,0xFFFF,0xFFFF,0xFFFF,0xFFFF,0xFFFF,0xFFFF,0x5DEF,0xA631,0x0000,0x0000,0x0000,0x0000,0x0000,0x0000,},
{0x0000,0x0000,0x0000,0x0000,0x0000,0x0000,0xE739,0x7DEF,0xFFFF,0xFFFF,0xFFFF,0xFFFF,0x59CE,0x9294,0x718C,0x9294,0xD39C,0x3CE7,0xFFFF,0xFFFF,0xFFFF,0xDFFF,0x0C63,0x0000,0x0000,0x0000,0x0000,0x0000,0x0000,0x0000,0xAA52,0x5DEF,0xFFFF,0xFFFF,0xFFFF,0xFFFF,0xFFFF,0xFFFF,0xFFFF,0xFFFF,0xFFFF,0xFFFF,0xFFFF,0x96B5,0x6108,0x0000,0x0000,0x0000,0x0000,0x0000,},
{0x0000,0x0000,0x0000,0x0000,0x0000,0x0000,0x55AD,0xFFFF,0xFFFF,0xFFFF,0xFFFF,0x3CE7,0x0421,0x0000,0x0000,0x0000,0x0000,0x8631,0xD7BD,0x9EF7,0x3CE7,0xD39C,0xC318,0x0000,0x0000,0x0000,0x0000,0x0000,0x0000,0x2842,0x7DEF,0xFFFF,0xFFFF,0xFFFF,0xFFFF,0xFFFF,0xFFFF,0xFFFF,0xFFFF,0xFFFF,0xFFFF,0xFFFF,0xFFFF,0xBEF7,0x694A,0x0000,0x0000,0x0000,0x0000,0x0000,},
{0x0000,0x0000,0x0000,0x0000,0x0000,0x494A,0xFFFF,0xFFFF,0xFFFF,0xFFFF,0xDFFF,0x6D6B,0x0000,0x0000,0x0000,0x0000,0x0000,0x0000,0x8210,0xC739,0x2842,0xC318,0x0000,0x0000,0x0000,0x0000,0x0000,0x0000,0xA210,0x18C6,0xFFFF,0xFFFF,0xFFFF,0xFFFF,0xFFFF,0xDBDE,0xB294,0x6D6B,0x6D6B,0x59CE,0xFFFF,0xFFFF,0xFFFF,0xFFFF,0x9294,0x0000,0x0000,0x0000,0x0000,0x0000,},
{0x0000,0x0000,0x0000,0x0000,0x6108,0xF7BD,0xFFFF,0xFFFF,0xFFFF,0xFFFF,0x718C,0x6108,0x0000,0x0000,0x0000,0x0000,0x0000,0x0000,0x0000,0x0000,0x0000,0x0000,0x0000,0x0000,0x0000,0x0000,0x0000,0x6108,0xB294,0xFFFF,0xFFFF,0xFFFF,0xFFFF,0xDFFF,0x14A5,0x0421,0x0000,0x0000,0x0000,0x694A,0xBEF7,0xFFFF,0xFFFF,0xFFFF,0x55AD,0x0000,0x0000,0x0000,0x0000,0x0000,},
{0x0000,0x0000,0x0000,0x0000,0xA631,0x3CE7,0xFFFF,0xFFFF,0xFFFF,0xDBDE,0xA631,0x2421,0x6529,0x2421,0x6108,0x0000,0x0000,0x0000,0x0000,0x0000,0x0000,0x0000,0x0000,0x0000,0x0000,0x0000,0x0000,0xEF7B,0xFFFF,0xFFFF,0xFFFF,0xFFFF,0xDFFF,0xAE73,0x0000,0x0000,0x0000,0x0000,0x0000,0x6108,0x9AD6,0xFFFF,0xFFFF,0xFFFF,0x96B5,0x0000,0x0000,0x0000,0x0000,0x0000,},
{0x0000,0x0000,0x0000,0x0000,0x0C63,0x9EF7,0xFFFF,0xFFFF,0xFFFF,0xFFFF,0x7DEF,0xDBDE,0xDBDE,0x9AD6,0x59CE,0xD7BD,0xD7BD,0xD7BD,0x96B5,0xD39C,0x2C63,0x0421,0x0000,0x0000,0x0000,0x0000,0x494A,0xFFFF,0xFFFF,0xFFFF,0xFFFF,0xBEF7,0xEB5A,0x0000,0x0000,0x0000,0x0000,0x0000,0x0000,0x0000,0xF7BD,0xFFFF,0xFFFF,0xFFFF,0xD7BD,0x0000,0x0000,0x0000,0x0000,0x0000,},
{0x0000,0x0000,0x0000,0x0000,0xCB5A,0x5DEF,0xFFFF,0xFFFF,0xFFFF,0xFFFF,0xFFFF,0xFFFF,0xFFFF,0xFFFF,0xFFFF,0xFFFF,0xFFFF,0xFFFF,0xFFFF,0xFFFF,0xFFFF,0x38C6,0x0421,0x0000,0x0000,0x6108,0x38C6,0xFFFF,0xFFFF,0xFFFF,0xFFFF,0x2C63,0x0000,0x0000,0x0000,0x0000,0x0000,0x0000,0x0000,0x0000,0xD7BD,0xFFFF,0xFFFF,0xFFFF,0xD7BD,0x0000,0x0000,0x0000,0x0000,0x0000,},
{0x0000,0x0000,0x0000,0x0000,0x0421,0x55AD,0xFFFF,0xFFFF,0xFFFF,0xFFFF,0xFFFF,0xFFFF,0xFFFF,0xFFFF,0xFFFF,0xFFFF,0xFFFF,0xFFFF,0xFFFF,0xFFFF,0xFFFF,0xFFFF,0x718C,0x0000,0x0000,0xAA52,0xBEF7,0xFFFF,0xFFFF,0xFFFF,0xF7BD,0x0000,0x0000,0x0000,0x0000,0x0000,0x0000,0x0000,0x0000,0x0000,0xD7BD,0xFFFF,0xFFFF,0xFFFF,0xD7BD,0x0000,0x0000,0x0000,0x0000,0x0000,},
{0x0000,0x0000,0x0000,0x0000,0x0000,0x0421,0xCF7B,0x1CE7,0xDFFF,0xFFFF,0xFFFF,0xFFFF,0xFFFF,0xFFFF,0xFFFF,0xFFFF,0xFFFF,0xFFFF,0xFFFF,0xFFFF,0xFFFF,0xFFFF,0xBAD6,0x6108,0x6108,0x75AD,0xFFFF,0xFFFF,0xFFFF,0xFFFF,0x718C,0x0000,0x0000,0x0000,0x0000,0x0000,0x0000,0x0000,0x0000,0x0000,0xD7BD,0xFFFF,0xFFFF,0xFFFF,0x18C6,0x0000,0x0000,0x0000,0x0000,0x0000,},
{0x0000,0x0000,0x0000,0x0000,0x0000,0x0000,0x0000,0x4529,0x4D6B,0x518C,0x34A5,0x34A5,0xF39C,0x34A5,0x96B5,0xD7BD,0xD7BD,0xF7BD,0x7DEF,0xFFFF,0xFFFF,0xFFFF,0x3CE7,0xA631,0xC318,0xD7BD,0xFFFF,0xFFFF,0xFFFF,0xDFFF,0xAA52,0x0000,0x0000,0x0000,0x0000,0x0000,0x0000,0x0000,0x0000,0x0000,0x96B5,0xFFFF,0xFFFF,0xFFFF,0xDBDE,0x0421,0x0000,0x0000,0x0000,0x0000,},
{0x0000,0x0000,0x0000,0x0000,0x0000,0x0000,0x0000,0x0000,0x0000,0x0000,0x0000,0x0000,0x0000,0x0000,0x0000,0x0000,0x0000,0x6108,0x34A5,0xFFFF,0xFFFF,0xFFFF,0x1CE7,0x494A,0x6108,0xD39C,0xFFFF,0xFFFF,0xFFFF,0xBEF7,0xCB5A,0x0000,0x0000,0x0000,0x0000,0x0000,0x0000,0x0000,0x0000,0x6108,0x75AD,0xFFFF,0xFFFF,0xFFFF,0xDBDE,0x0842,0x0000,0x0000,0x0000,0x0000,},
{0x0000,0x0000,0x0000,0x0000,0x0000,0x0000,0x0000,0x0000,0x0000,0x4529,0x8E73,0x2C63,0x0421,0x0000,0x0000,0x0000,0x0000,0xA631,0xDBDE,0xFFFF,0xFFFF,0xFFFF,0xBAD6,0x0421,0x0000,0x3084,0xFFFF,0xFFFF,0xFFFF,0xFFFF,0xEF7B,0x0000,0x0000,0x0000,0x0000,0x0000,0x0000,0x0000,0x0000,0xE739,0x1CE7,0xFFFF,0xFFFF,0xFFFF,0x9AD6,0x0421,0x0000,0x0000,0x0000,0x0000,},
{0x0000,0x0000,0x0000,0x0000,0x0000,0x0000,0x0000,0x0000,0x4529,0x38C6,0xFFFF,0xFFFF,0xDBDE,0x718C,0x6D6B,0xCF7B,0x55AD,0x3CE7,0xFFFF,0xFFFF,0xFFFF,0xFFFF,0x34A5,0x0000,0x0000,0x518C,0xFFFF,0xFFFF,0xFFFF,0xFFFF,0xFBDE,0xAE73,0xE739,0x2421,0x6108,0x0000,0x6108,0xA631,0xB294,0x7DEF,0xFFFF,0xFFFF,0xFFFF,0xFFFF,0xB294,0x0000,0x0000,0x0000,0x0000,0x0000,},
{0x0000,0x0000,0x0000,0x0000,0x0000,0x0000,0x0000,0x0000,0xCF7B,0xFFFF,0xFFFF,0xFFFF,0xFFFF,0xFFFF,0xDFFF,0xFFFF,0xFFFF,0xFFFF,0xFFFF,0xFFFF,0xFFFF,0xFFFF,0x0842,0x0000,0x0000,0x694A,0xBEF7,0xFFFF,0xFFFF,0xFFFF,0xFFFF,0xDFFF,0x7DEF,0xBAD6,0x59CE,0xF7BD,0x79CE,0x7DEF,0xFFFF,0xFFFF,0xFFFF,0xFFFF,0xFFFF,0x9EF7,0x8631,0x0000,0x0000,0x0000,0x0000,0x0000,},
{0x0000,0x0000,0x0000,0x0000,0x0000,0x0000,0x0000,0x0000,0x3084,0xFFFF,0xFFFF,0xFFFF,0xFFFF,0xFFFF,0xFFFF,0xFFFF,0xFFFF,0xFFFF,0xFFFF,0xFFFF,0xFFFF,0xB294,0x0000,0x0000,0x0000,0x6108,0x34A5,0xFFFF,0xFFFF,0xFFFF,0xFFFF,0xFFFF,0xFFFF,0xFFFF,0xFFFF,0xFFFF,0xFFFF,0xFFFF,0xFFFF,0xFFFF,0xFFFF,0xFFFF,0xFFFF,0x9294,0x0000,0x0000,0x0000,0x0000,0x0000,0x0000,},
{0x0000,0x0000,0x0000,0x0000,0x0000,0x0000,0x0000,0x0000,0x8631,0x5DEF,0xFFFF,0xFFFF,0xFFFF,0xFFFF,0xFFFF,0xFFFF,0xFFFF,0xFFFF,0xFFFF,0xFFFF,0x18C6,0x0421,0x0000,0x0000,0x0000,0x0000,0x4529,0x79CE,0xFFFF,0xFFFF,0xFFFF,0xFFFF,0xFFFF,0xFFFF,0xFFFF,0xFFFF,0xFFFF,0xFFFF,0xFFFF,0xFFFF,0xFFFF,0xFFFF,0x18C6,0x0421,0x0000,0x0000,0x0000,0x0000,0x0000,0x0000,},
{0x0000,0x0000,0x0000,0x0000,0x0000,0x0000,0x0000,0x0000,0x0000,0x694A,0x9AD6,0xDFFF,0xFFFF,0xFFFF,0xFFFF,0xFFFF,0xFFFF,0xBEF7,0xF7BD,0xAE73,0x0421,0x0000,0x0000,0x0000,0x0000,0x0000,0x0000,0x0421,0x34A5,0xBEF7,0xFFFF,0xFFFF,0xFFFF,0xFFFF,0xFFFF,0xFFFF,0xFFFF,0xFFFF,0xFFFF,0xDFFF,0x3CE7,0x1084,0x0421,0x0000,0x0000,0x0000,0x0000,0x0000,0x0000,0x0000,},
{0x0000,0x0000,0x0000,0x0000,0x0000,0x0000,0x0000,0x0000,0x0000,0x0000,0x0421,0x6D6B,0x9294,0xEF7B,0xAE73,0x9294,0x9294,0xE739,0x0000,0x0000,0x0000,0x0000,0x0000,0x0000,0x0000,0x0000,0x0000,0x0000,0x0000,0xE739,0x1084,0x518C,0xB294,0x34A5,0x96B5,0xD7BD,0x96B5,0xD39C,0xCF7B,0xCB5A,0x0421,0x0000,0x0000,0x0000,0x0000,0x0000,0x0000,0x0000,0x0000,0x0000,},
{0x0000,0x0000,0x0000,0x0000,0x0000,0x0000,0x0000,0x0000,0x0000,0x0000,0x0000,0x0000,0x0000,0x0000,0x0000,0x0000,0x0000,0x0000,0x0000,0x0000,0x0000,0x0000,0x0000,0x0000,0x0000,0x0000,0x0000,0x0000,0x0000,0x0000,0x0000,0x0000,0x0000,0x0000,0x0000,0x0000,0x0000,0x0000,0x0000,0x0000,0x0000,0x0000,0x0000,0x0000,0x0000,0x0000,0x0000,0x0000,0x0000,0x0000,},
{0x0000,0x0000,0x0000,0x0000,0x0000,0x0000,0x0000,0x0000,0x0000,0x0000,0x0000,0x0000,0x0000,0x0000,0x0000,0x0000,0x0000,0x0000,0x0000,0x0000,0x0000,0x0000,0x0000,0x0000,0x0000,0x0000,0x0000,0x0000,0x0000,0x0000,0x0000,0x0000,0x0000,0x0000,0x0000,0x0000,0x0000,0x0000,0x0000,0x0000,0x0000,0x0000,0x0000,0x0000,0x0000,0x0000,0x0000,0x0000,0x0000,0x0000,},
{0x0000,0x0000,0x0000,0x0000,0x0000,0x0000,0x0000,0x0000,0x0000,0x0000,0x0000,0x0000,0x0000,0x0000,0x0000,0x0000,0x0000,0x0000,0x0000,0x0000,0x0000,0x0000,0x0000,0x0000,0x0000,0x0000,0x0000,0x0000,0x0000,0x0000,0x0000,0x0000,0x0000,0x0000,0x0000,0x0000,0x0000,0x0000,0x0000,0x0000,0x0000,0x0000,0x0000,0x0000,0x0000,0x0000,0x0000,0x0000,0x0000,0x0000,},
{0x0000,0x0000,0x0000,0x0000,0x0000,0x0000,0x0000,0x0000,0x0000,0x0000,0x0000,0x0000,0x0421,0xCF7B,0x75AD,0x55AD,0xF39C,0xB294,0x518C,0x518C,0x694A,0x6108,0x0000,0x0000,0x0000,0x0000,0x0000,0x0000,0x8210,0x494A,0xAE73,0xAE73,0x6D6B,0x6D6B,0x6D6B,0x8E73,0xCF7B,0xCF7B,0x8E73,0x6D6B,0x6D6B,0x6D6B,0x6D6B,0xCB5A,0x0421,0x0000,0x0000,0x0000,0x0000,0x0000,},
{0x0000,0x0000,0x0000,0x0000,0x0000,0x0000,0x0000,0x0000,0x0000,0x0000,0x6108,0x2C63,0xFBDE,0xFFFF,0xFFFF,0xFFFF,0xFFFF,0xFFFF,0xFFFF,0xFFFF,0xBEF7,0xF7BD,0xE739,0x0000,0x0000,0x0000,0x0000,0x8210,0xAE73,0x3CE7,0xDFFF,0xDFFF,0xDFFF,0xDFFF,0xDFFF,0xDFFF,0xFFFF,0xFFFF,0xDFFF,0xDFFF,0xDFFF,0xDFFF,0xBEF7,0x5DEF,0x55AD,0x0421,0x0000,0x0000,0x0000,0x0000,},
{0x0000,0x0000,0x0000,0x0000,0x0000,0x0000,0x0000,0x0000,0x0000,0x4529,0x34A5,0xBEF7,0xFFFF,0xFFFF,0xFFFF,0xFFFF,0xFFFF,0xFFFF,0xFFFF,0xFFFF,0xFFFF,0xFFFF,0x3CE7,0x8631,0x0000,0x0000,0x0000,0x8631,0x79CE,0xFFFF,0xFFFF,0xFFFF,0xFFFF,0xFFFF,0xFFFF,0xFFFF,0xFFFF,0xFFFF,0xFFFF,0xFFFF,0xFFFF,0xFFFF,0xFFFF,0xFFFF,0xFFFF,0x0C63,0x0000,0x0000,0x0000,0x0000,},
{0x0000,0x0000,0x0000,0x0000,0x0000,0x0000,0x0000,0x0000,0x694A,0xBAD6,0xFFFF,0xFFFF,0xFFFF,0xFFFF,0xFFFF,0xFFFF,0xFFFF,0xFFFF,0xFFFF,0xFFFF,0xFFFF,0xFFFF,0x9EF7,0x2C63,0x0000,0x0000,0x0000,0x8631,0x79CE,0xFFFF,0xFFFF,0xFFFF,0xFFFF,0xFFFF,0xFFFF,0xFFFF,0xFFFF,0xFFFF,0xFFFF,0xFFFF,0xFFFF,0xFFFF,0xFFFF,0xFFFF,0xFFFF,0x0C63,0x0000,0x0000,0x0000,0x0000,},
{0x0000,0x0000,0x0000,0x0000,0x0000,0x0000,0x0000,0x8631,0x7DEF,0xFFFF,0xFFFF,0xFFFF,0xFFFF,0xFFFF,0xFFFF,0xBEF7,0x3CE7,0x7DEF,0xDFFF,0xFFFF,0xFFFF,0xFFFF,0x1CE7,0x8631,0x0000,0x0000,0x0000,0x8210,0xAE73,0x3CE7,0xDFFF,0xDFFF,0xDFFF,0xDFFF,0xFFFF,0xFFFF,0xFFFF,0xFFFF,0xFFFF,0xDFFF,0xDFFF,0xDFFF,0xBEF7,0x5DEF,0x75AD,0x0421,0x0000,0x0000,0x0000,0x0000,},
{0x0000,0x0000,0x0000,0x0000,0x0000,0x0000,0x0000,0x14A5,0xFFFF,0xFFFF,0xFFFF,0xFFFF,0xFFFF,0x7DEF,0x9294,0x494A,0x8631,0x0842,0xAE73,0x14A5,0x75AD,0x9294,0xA631,0x0000,0x0000,0x0000,0x0000,0x0000,0x8210,0x494A,0xAE73,0xAE73,0x6D6B,0x6D6B,0x38C6,0xFFFF,0xFFFF,0xFFFF,0x7DEF,0x3084,0x6D6B,0x6D6B,0x6D6B,0xCB5A,0x0421,0x0000,0x0000,0x0000,0x0000,0x0000,},
{0x0000,0x0000,0x0000,0x0000,0x0000,0x0000,0x0421,0xFBDE,0xFFFF,0xFFFF,0xFFFF,0xFFFF,0x9AD6,0x2C63,0x6108,0x0000,0x0000,0x0000,0x0000,0x0000,0x0000,0x0000,0x0000,0x0000,0x0000,0x0000,0x0000,0x0000,0x0000,0x0000,0x0000,0x0000,0x0000,0x0000,0xF39C,0xFFFF,0xFFFF,0xFFFF,0xFBDE,0x6529,0x0000,0x0000,0x0000,0x0000,0x0000,0x0000,0x0000,0x0000,0x0000,0x0000,},
{0x0000,0x0000,0x0000,0x0000,0x0000,0x0000,0x0842,0xDBDE,0xFFFF,0xFFFF,0xFFFF,0xFFFF,0xFFFF,0x5DEF,0x38C6,0x518C,0xCB5A,0x0421,0x0000,0x0000,0x0000,0x0000,0x0000,0x0000,0x0000,0x0000,0x0000,0x0000,0x0000,0x0000,0x0000,0x0000,0x0000,0x0000,0xF39C,0xFFFF,0xFFFF,0xFFFF,0xFBDE,0x6529,0x0000,0x0000,0x0000,0x0000,0x0000,0x0000,0x0000,0x0000,0x0000,0x0000,},
{0x0000,0x0000,0x0000,0x0000,0x0000,0x0000,0x0421,0x38C6,0xFFFF,0xFFFF,0xFFFF,0xFFFF,0xFFFF,0xFFFF,0xFFFF,0xFFFF,0x9EF7,0xDBDE,0x14A5,0x9294,0x6D6B,0x0421,0x0000,0x0000,0x0000,0x0000,0x0000,0x0000,0x0000,0x0000,0x0000,0x0000,0x0000,0x0000,0xF39C,0xFFFF,0xFFFF,0xFFFF,0xFBDE,0x6529,0x0000,0x0000,0x0000,0x0000,0x0000,0x0000,0x0000,0x0000,0x0000,0x0000,},
{0x0000,0x0000,0x0000,0x0000,0x0000,0x0000,0x0000,0x694A,0x5DEF,0xFFFF,0xFFFF,0xFFFF,0xFFFF,0xFFFF,0xFFFF,0xFFFF,0xFFFF,0xFFFF,0xFFFF,0xFFFF,0xDFFF,0x9AD6,0x694A,0x0000,0x0000,0x0000,0x0000,0x0000,0x0000,0x0000,0x0000,0x0000,0x0000,0x0000,0xF39C,0xFFFF,0xFFFF,0xFFFF,0xFBDE,0x6529,0x0000,0x0000,0x0000,0x0000,0x0000,0x0000,0x0000,0x0000,0x0000,0x0000,},
{0x0000,0x0000,0x0000,0x0000,0x0000,0x0000,0x0000,0x0000,0xA631,0xD39C,0x3CE7,0xDFFF,0xFFFF,0xFFFF,0xFFFF,0xFFFF,0xFFFF,0xFFFF,0xFFFF,0xFFFF,0xFFFF,0xFFFF,0x7DEF,0x8631,0x0000,0x0000,0x0000,0x0000,0x0000,0x0000,0x0000,0x0000,0x0000,0x0000,0xF39C,0xFFFF,0xFFFF,0xFFFF,0xFBDE,0x6529,0x0000,0x0000,0x0000,0x0000,0x0000,0x0000,0x0000,0x0000,0x0000,0x0000,},
{0x0000,0x0000,0x0000,0x0000,0x0000,0x0000,0x0000,0x0000,0x0000,0x0000,0x4529,0x4D6B,0x1084,0x55AD,0xFBDE,0x9EF7,0xFFFF,0xFFFF,0xFFFF,0xFFFF,0xFFFF,0xFFFF,0xFFFF,0x718C,0x0000,0x0000,0x0000,0x0000,0x0000,0x0000,0x0000,0x0000,0x0000,0x0000,0xF39C,0xFFFF,0xFFFF,0xFFFF,0xFBDE,0x6529,0x0000,0x0000,0x0000,0x0000,0x0000,0x0000,0x0000,0x0000,0x0000,0x0000,},
{0x0000,0x0000,0x0000,0x0000,0x2000,0x2421,0xC739,0xC318,0x0000,0x0000,0x0000,0x0000,0x0000,0x0000,0x0421,0xCB5A,0x9294,0x1CE7,0xFFFF,0xFFFF,0xFFFF,0xFFFF,0xFFFF,0xB294,0x0000,0x0000,0x0000,0x0000,0x0000,0x0000,0x0000,0x0000,0x0000,0x0000,0xF39C,0xFFFF,0xFFFF,0xFFFF,0xFBDE,0x6529,0x0000,0x0000,0x0000,0x0000,0x0000,0x0000,0x0000,0x0000,0x0000,0x0000,},
{0x0000,0x0000,0x0000,0x2000,0xC739,0x55AD,0x79CE,0xF7BD,0x494A,0x0000,0x0000,0x0000,0x0000,0x0000,0x0000,0x0000,0x0000,0xE739,0x3CE7,0xFFFF,0xFFFF,0xFFFF,0xBEF7,0xE739,0x0000,0x0000,0x0000,0x0000,0x0000,0x0000,0x0000,0x0000,0x0000,0x0000,0xF39C,0xFFFF,0xFFFF,0xFFFF,0xFBDE,0x6529,0x0000,0x0000,0x0000,0x0000,0x0000,0x0000,0x0000,0x0000,0x0000,0x0000,},
{0x0000,0x0000,0x0000,0x8210,0x3084,0xFFFF,0xFFFF,0xFFFF,0x9EF7,0xD39C,0x9294,0xEF7B,0x6D6B,0x6D6B,0xEF7B,0x9294,0x518C,0x38C6,0xFFFF,0xFFFF,0xFFFF,0xFFFF,0x75AD,0x0000,0x0000,0x0000,0x0000,0x0000,0x0000,0x0000,0x0000,0x0000,0x0000,0x0000,0xF39C,0xFFFF,0xFFFF,0xFFFF,0xFBDE,0x6529,0x0000,0x0000,0x0000,0x0000,0x0000,0x0000,0x0000,0x0000,0x0000,0x0000,},
{0x0000,0x0000,0x0000,0x8210,0x718C,0xFFFF,0xFFFF,0xFFFF,0xFFFF,0xFFFF,0xFFFF,0xFFFF,0xDFFF,0xDFFF,0xFFFF,0xFFFF,0xFFFF,0xFFFF,0xFFFF,0xFFFF,0xFFFF,0xFFFF,0x2C63,0x0000,0x0000,0x0000,0x0000,0x0000,0x0000,0x0000,0x0000,0x0000,0x0000,0x0000,0xF39C,0xFFFF,0xFFFF,0xFFFF,0xFBDE,0x6529,0x0000,0x0000,0x0000,0x0000,0x0000,0x0000,0x0000,0x0000,0x0000,0x0000,},
{0x0000,0x0000,0x0000,0x2000,0x0842,0x1CE7,0xFFFF,0xFFFF,0xFFFF,0xFFFF,0xFFFF,0xFFFF,0xFFFF,0xFFFF,0xFFFF,0xFFFF,0xFFFF,0xFFFF,0xFFFF,0xFFFF,0xFFFF,0xFBDE,0x0421,0x0000,0x0000,0x0000,0x0000,0x0000,0x0000,0x0000,0x0000,0x0000,0x0000,0x0000,0xF39C,0xFFFF,0xFFFF,0xFFFF,0xFBDE,0x6529,0x0000,0x0000,0x0000,0x0000,0x0000,0x0000,0x0000,0x0000,0x0000,0x0000,},
{0x0000,0x0000,0x0000,0x0000,0x2000,0x6D6B,0xFFFF,0xFFFF,0xFFFF,0xFFFF,0xFFFF,0xFFFF,0xFFFF,0xFFFF,0xFFFF,0xFFFF,0xFFFF,0xFFFF,0xFFFF,0xFFFF,0xBEF7,0xAA52,0x0000,0x0000,0x0000,0x0000,0x0000,0x0000,0x0000,0x0000,0x0000,0x0000,0x0000,0x0000,0xF39C,0xFFFF,0xFFFF,0xFFFF,0xFBDE,0x6529,0x0000,0x0000,0x0000,0x0000,0x0000,0x0000,0x0000,0x0000,0x0000,0x0000,},
{0x0000,0x0000,0x0000,0x0000,0x0000,0x6108,0xCF7B,0xFBDE,0xBEF7,0xFFFF,0xFFFF,0xFFFF,0xDFFF,0xDFFF,0xFFFF,0xFFFF,0xDFFF,0x5DEF,0x9AD6,0x34A5,0xE739,0x0000,0x0000,0x0000,0x0000,0x0000,0x0000,0x0000,0x0000,0x0000,0x0000,0x0000,0x0000,0x0000,0x3084,0xFFFF,0xFFFF,0xFFFF,0x38C6,0x2421,0x0000,0x0000,0x0000,0x0000,0x0000,0x0000,0x0000,0x0000,0x0000,0x0000,},
{0x0000,0x0000,0x0000,0x0000,0x0000,0x0000,0x6108,0xA631,0x0C63,0xEF7B,0x9294,0xEF7B,0x6D6B,0x6D6B,0xEF7B,0x9294,0xAE73,0xA631,0x6108,0x0000,0x0000,0x0000,0x0000,0x0000,0x0000,0x0000,0x0000,0x0000,0x0000,0x0000,0x0000,0x0000,0x0000,0x0000,0x8631,0x1CE7,0xFFFF,0xFFFF,0x6D6B,0x6108,0x0000,0x0000,0x0000,0x0000,0x0000,0x0000,0x0000,0x0000,0x0000,0x0000,},
{0x0000,0x0000,0x0000,0x0000,0x0000,0x0000,0x0000,0x0000,0x0000,0x0000,0x0000,0x0000,0x0000,0x0000,0x0000,0x0000,0x0000,0x0000,0x0000,0x0000,0x0000,0x0000,0x0000,0x0000,0x0000,0x0000,0x0000,0x0000,0x0000,0x0000,0x0000,0x0000,0x0000,0x0000,0x0000,0xA631,0xAE73,0x694A,0x6108,0x0000,0x0000,0x0000,0x0000,0x0000,0x0000,0x0000,0x0000,0x0000,0x0000,0x0000,},
{0x0000,0x0000,0x0000,0x0000,0x0000,0x0000,0x0000,0x0000,0x0000,0x0000,0x0000,0x0000,0x0000,0x0000,0x0000,0x0000,0x0000,0x0000,0x0000,0x0000,0x0000,0x0000,0x0000,0x0000,0x0000,0x0000,0x0000,0x0000,0x0000,0x0000,0x0000,0x0000,0x0000,0x0000,0x0000,0x0000,0x0000,0x0000,0x0000,0x0000,0x0000,0x0000,0x0000,0x0000,0x0000,0x0000,0x0000,0x0000,0x0000,0x0000,},
{0x0000,0x0000,0x0000,0x0000,0x0000,0x0000,0x0000,0x0000,0x0000,0x0000,0x0000,0x0000,0x0000,0x0000,0x0000,0x0000,0x0000,0x0000,0x0000,0x0000,0x0000,0x0000,0x0000,0x0000,0x0000,0x0000,0x0000,0x0000,0x0000,0x0000,0x0000,0x0000,0x0000,0x0000,0x0000,0x0000,0x0000,0x0000,0x0000,0x0000,0x0000,0x0000,0x0000,0x0000,0x0000,0x0000,0x0000,0x0000,0x0000,0xA210,},
};

// Plus Cursor
const uint16_t cursor[][5] = {
{0x0000,0x0000,0xFFFF,0x0000,0x0000,},
{0x0000,0x0000,0xFFFF,0x0000,0x0000,},
{0xFFFF,0xFFFF,0xFFFF,0xFFFF,0xFFFF,},
{0x0000,0x0000,0xFFFF,0x0000,0x0000,},
{0x0000,0x0000,0xFFFF,0x0000,0x0000,},
};

/* USER CODE END PV */

void SystemClock_Config(void);
static void MX_GPIO_Init(void);
static void MX_DMA_Init(void);
static void MX_SPI1_Init(void);
static void MX_I2C1_Init(void);
static void MX_RTC_Init(void);
void StartDefaultTask(void const * argument);
void start_baca_sht(void const * argument);
void start_display(void const * argument);
void start_input_poll(void const * argument);
void start_game_master(void const * argument);

/* USER CODE BEGIN PFP */
void display_init() {
    ILI9341_Unselect();
    ILI9341_TouchUnselect();
    ILI9341_Init();
}

void init_cursor(uint16_t x, uint16_t y){
	ILI9341_DrawImage(x,y,5,5,(const uint16_t*)cursor);
}

void drawCursor (uint16_t x, uint16_t y, uint16_t x_old, uint16_t y_old){
	ILI9341_FillRectangle(x_old,y_old,5,5,ILI9341_BLACK);
	init_cursor(x,y);
}

void initPong(){
	user.x = 250;
	user.y = 170;
	user.width = PADDLE_WIDTH;
	user.height = PADDLE_HEIGHT;
	user.speed = PADDLE_SPEED;
	bot.x = 70-PADDLE_WIDTH;
	bot.y = 170;
	bot.width = PADDLE_WIDTH;
	bot.height = PADDLE_HEIGHT;
	bot.speed = PADDLE_SPEED;
	bola.x=160;
	bola.y=170;
	bola.velx=BALL_VELX;
	bola.vely=BALL_VELY;
	bola.rad=BALL_SIZE;
	// init paddle dan bola di display
	ILI9341_FillRectangle(user.x,user.y,PADDLE_WIDTH,PADDLE_HEIGHT,ILI9341_WHITE);
	ILI9341_FillRectangle(bot.x,bot.y,PADDLE_WIDTH,PADDLE_HEIGHT,ILI9341_WHITE);

	ILI9341_FillRectangle(bola.x-bola.rad/2,bola.y-bola.rad/2,bola.rad,bola.rad,ILI9341_WHITE);
}

void updateBallPos(uint16_t x, uint16_t y, uint16_t x_old, uint16_t y_old){
	ILI9341_FillRectangle(x_old-bola.rad/2,y_old-bola.rad/2,bola.rad,bola.rad,ILI9341_BLACK);
	ILI9341_FillRectangle(x-bola.rad/2,y-bola.rad/2,bola.rad,bola.rad,ILI9341_WHITE);
}

void updatePaddlePos(uint16_t x, uint16_t y, uint16_t x_old, uint16_t y_old){
	//ILI9341_FillRectangle(x_old-(PADDLE_WIDTH/2),y_old-(PADDLE_HEIGHT/2),PADDLE_WIDTH,PADDLE_HEIGHT,ILI9341_BLACK);
	//ILI9341_FillRectangle(x-(PADDLE_WIDTH/2),y-(PADDLE_HEIGHT/2),PADDLE_WIDTH,PADDLE_HEIGHT,ILI9341_WHITE);
	ILI9341_FillRectangle(x_old,y_old,PADDLE_WIDTH,PADDLE_HEIGHT,ILI9341_BLACK);
	ILI9341_FillRectangle(x,y,PADDLE_WIDTH,PADDLE_HEIGHT,ILI9341_WHITE);
}

void resetBallStatus(){
	ILI9341_FillRectangle(bola.x-bola.rad/2,bola.y-bola.rad/2,bola.rad,bola.rad,ILI9341_BLACK);
	int rand_vx;
	int rand_vy;
	bola.x=160;
	bola.y=170;
	random_number = rand();
	srand(random_number);
	rand_vx = random_number % 2;
	random_number = rand();
	rand_vy = random_number % 2;
	if(rand_vx==1)
	{
		bola.velx=BALL_VELX;
	}
	else
	{
		bola.velx=-BALL_VELX;
	}

	if(rand_vy==1)
	{
		bola.vely=BALL_VELY;
	}
	else
	{
		bola.vely=-BALL_VELY;
	}
	bola.rad=BALL_SIZE;
}
/* USER CODE END PFP */

int main(void)
{

  /* MCU Configuration--------------------------------------------------------*/

  /* Reset of all peripherals, Initializes the Flash interface and the Systick. */
  HAL_Init();

  /* Configure the system clock */
  SystemClock_Config();

  /* Initialize all configured peripherals */
  MX_GPIO_Init();
  MX_DMA_Init();
  MX_SPI1_Init();
  MX_I2C1_Init();
  MX_RTC_Init();
  /* USER CODE BEGIN 2 */
  display_init();
  SHT2x_Init(&hi2c1);
  SHT2x_SetResolution(RES_14_12);
  ILI9341_FillScreen(ILI9341_BLACK);

  // INIT AREA UNTUK NAMA
  ILI9341_FillRectangle(0,0,ILI9341_HEIGHT,40,ILI9341_WHITE);
  ILI9341_FillRectangle(5,5,ILI9341_HEIGHT-10,30,ILI9341_BLACK);
  ILI9341_WriteString(10, 10, "BINTANG DAN RAKKA - TEAM 5", Font_11x18, 0xf800, ILI9341_BLACK);

  // AREA UNTUK MENGGAMBAR ATAU PONG ???
  ILI9341_FillRectangle(0,100,ILI9341_HEIGHT,140,ILI9341_WHITE);
  ILI9341_FillRectangle(5,105,ILI9341_HEIGHT-10,130,ILI9341_BLACK);

  // (x,y,width,height,color)
  // scoreboard kiri
  ILI9341_FillRectangle(0,100,60,40,ILI9341_WHITE);
  ILI9341_FillRectangle(5,105,50,30,ILI9341_BLACK);

  // scoreboard kanan
  ILI9341_FillRectangle(260,100,60,40,ILI9341_WHITE);
  ILI9341_FillRectangle(265,105,50,30,ILI9341_BLACK);

  // gambar petir
  ILI9341_DrawImage(260,45,50,50,(const uint16_t*)test_img_50x50);

  // init cursor awal di x = 160 dan y = 170
  x=160;
  y=170;
  oldx=x;
  oldy=y;

  //init_cursor(x,y);

  // init paddle dan bola

  initPong();

  ouserx=user.x;
  ousery=user.y;
  obotx=bot.x;
  oboty=bot.y;

  // init score
  scoreL=0;
  scoreR=0;

  /* USER CODE END 2 */

  /* Create the semaphores(s) */
  /* definition and creation of disp_semaphore */
  osSemaphoreDef(disp_semaphore);
  disp_semaphoreHandle = osSemaphoreCreate(osSemaphore(disp_semaphore), 1);

  /* Create the thread(s) */
  /* definition and creation of defaultTask */
  osThreadDef(defaultTask, StartDefaultTask, osPriorityNormal, 0, 128);
  defaultTaskHandle = osThreadCreate(osThread(defaultTask), NULL);

  /* definition and creation of baca_sht */
  osThreadDef(baca_sht, start_baca_sht, osPriorityLow, 0, 512);
  baca_shtHandle = osThreadCreate(osThread(baca_sht), NULL);

  /* definition and creation of display */
  osThreadDef(display, start_display, osPriorityAboveNormal, 0, 1024);
  displayHandle = osThreadCreate(osThread(display), NULL);

  /* definition and creation of input_poll */
  osThreadDef(input_poll, start_input_poll, osPriorityNormal, 0, 256);
  input_pollHandle = osThreadCreate(osThread(input_poll), NULL);

  /* definition and creation of game_master */
  osThreadDef(game_master, start_game_master, osPriorityBelowNormal, 0, 1024);
  game_masterHandle = osThreadCreate(osThread(game_master), NULL);

  /* Start scheduler */
  osKernelStart();

  /* We should never get here as control is now taken by the scheduler */
  /* Infinite loop */
  while (1)
  {

  }
}

void SystemClock_Config(void)
{
  RCC_OscInitTypeDef RCC_OscInitStruct = {0};
  RCC_ClkInitTypeDef RCC_ClkInitStruct = {0};

  /** Configure the main internal regulator output voltage
  */
  __HAL_RCC_PWR_CLK_ENABLE();
  __HAL_PWR_VOLTAGESCALING_CONFIG(PWR_REGULATOR_VOLTAGE_SCALE1);

  /** Initializes the RCC Oscillators according to the specified parameters
  * in the RCC_OscInitTypeDef structure.
  */
  RCC_OscInitStruct.OscillatorType = RCC_OSCILLATORTYPE_HSI|RCC_OSCILLATORTYPE_LSI;
  RCC_OscInitStruct.HSIState = RCC_HSI_ON;
  RCC_OscInitStruct.HSICalibrationValue = RCC_HSICALIBRATION_DEFAULT;
  RCC_OscInitStruct.LSIState = RCC_LSI_ON;
  RCC_OscInitStruct.PLL.PLLState = RCC_PLL_ON;
  RCC_OscInitStruct.PLL.PLLSource = RCC_PLLSOURCE_HSI;
  RCC_OscInitStruct.PLL.PLLM = 8;
  RCC_OscInitStruct.PLL.PLLN = 100;
  RCC_OscInitStruct.PLL.PLLP = RCC_PLLP_DIV2;
  RCC_OscInitStruct.PLL.PLLQ = 4;
  if (HAL_RCC_OscConfig(&RCC_OscInitStruct) != HAL_OK)
  {
    Error_Handler();
  }

  /** Initializes the CPU, AHB and APB buses clocks
  */
  RCC_ClkInitStruct.ClockType = RCC_CLOCKTYPE_HCLK|RCC_CLOCKTYPE_SYSCLK
                              |RCC_CLOCKTYPE_PCLK1|RCC_CLOCKTYPE_PCLK2;
  RCC_ClkInitStruct.SYSCLKSource = RCC_SYSCLKSOURCE_PLLCLK;
  RCC_ClkInitStruct.AHBCLKDivider = RCC_SYSCLK_DIV1;
  RCC_ClkInitStruct.APB1CLKDivider = RCC_HCLK_DIV2;
  RCC_ClkInitStruct.APB2CLKDivider = RCC_HCLK_DIV1;

  if (HAL_RCC_ClockConfig(&RCC_ClkInitStruct, FLASH_LATENCY_3) != HAL_OK)
  {
    Error_Handler();
  }
}

static void MX_I2C1_Init(void)
{

  hi2c1.Instance = I2C1;
  hi2c1.Init.ClockSpeed = 100000;
  hi2c1.Init.DutyCycle = I2C_DUTYCYCLE_2;
  hi2c1.Init.OwnAddress1 = 0;
  hi2c1.Init.AddressingMode = I2C_ADDRESSINGMODE_7BIT;
  hi2c1.Init.DualAddressMode = I2C_DUALADDRESS_DISABLE;
  hi2c1.Init.OwnAddress2 = 0;
  hi2c1.Init.GeneralCallMode = I2C_GENERALCALL_DISABLE;
  hi2c1.Init.NoStretchMode = I2C_NOSTRETCH_DISABLE;
  if (HAL_I2C_Init(&hi2c1) != HAL_OK)
  {
    Error_Handler();
  }

}

static void MX_RTC_Init(void)
{

  RTC_TimeTypeDef sTime = {0};
  RTC_DateTypeDef sDate = {0};

  /** Initialize RTC Only
  */
  hrtc.Instance = RTC;
  hrtc.Init.HourFormat = RTC_HOURFORMAT_24;
  hrtc.Init.AsynchPrediv = 127;
  hrtc.Init.SynchPrediv = 255;
  hrtc.Init.OutPut = RTC_OUTPUT_DISABLE;
  hrtc.Init.OutPutPolarity = RTC_OUTPUT_POLARITY_HIGH;
  hrtc.Init.OutPutType = RTC_OUTPUT_TYPE_OPENDRAIN;
  if (HAL_RTC_Init(&hrtc) != HAL_OK)
  {
    Error_Handler();
  }

  /** Initialize RTC and set the Time and Date
  */
  sTime.Hours = 0x0;
  sTime.Minutes = 0x0;
  sTime.Seconds = 0x0;
  sTime.DayLightSaving = RTC_DAYLIGHTSAVING_NONE;
  sTime.StoreOperation = RTC_STOREOPERATION_RESET;
  if (HAL_RTC_SetTime(&hrtc, &sTime, RTC_FORMAT_BCD) != HAL_OK)
  {
    Error_Handler();
  }
  sDate.WeekDay = RTC_WEEKDAY_SUNDAY;
  sDate.Month = RTC_MONTH_SEPTEMBER;
  sDate.Date = 0x22;
  sDate.Year = 0x24;

  if (HAL_RTC_SetDate(&hrtc, &sDate, RTC_FORMAT_BCD) != HAL_OK)
  {
    Error_Handler();
  }

}

static void MX_SPI1_Init(void)
{

  /* SPI1 parameter configuration*/
  hspi1.Instance = SPI1;
  hspi1.Init.Mode = SPI_MODE_MASTER;
  hspi1.Init.Direction = SPI_DIRECTION_2LINES;
  hspi1.Init.DataSize = SPI_DATASIZE_8BIT;
  hspi1.Init.CLKPolarity = SPI_POLARITY_LOW;
  hspi1.Init.CLKPhase = SPI_PHASE_1EDGE;
  hspi1.Init.NSS = SPI_NSS_SOFT;
  hspi1.Init.BaudRatePrescaler = SPI_BAUDRATEPRESCALER_4;
  hspi1.Init.FirstBit = SPI_FIRSTBIT_MSB;
  hspi1.Init.TIMode = SPI_TIMODE_DISABLE;
  hspi1.Init.CRCCalculation = SPI_CRCCALCULATION_DISABLE;
  hspi1.Init.CRCPolynomial = 10;
  if (HAL_SPI_Init(&hspi1) != HAL_OK)
  {
    Error_Handler();
  }

}

static void MX_DMA_Init(void)
{

  /* DMA controller clock enable */
  __HAL_RCC_DMA2_CLK_ENABLE();

  /* DMA interrupt init */
  /* DMA2_Stream2_IRQn interrupt configuration */
  HAL_NVIC_SetPriority(DMA2_Stream2_IRQn, 5, 0);
  HAL_NVIC_EnableIRQ(DMA2_Stream2_IRQn);

}

static void MX_GPIO_Init(void)
{
  GPIO_InitTypeDef GPIO_InitStruct = {0};

  /* GPIO Ports Clock Enable */
  __HAL_RCC_GPIOC_CLK_ENABLE();
  __HAL_RCC_GPIOH_CLK_ENABLE();
  __HAL_RCC_GPIOA_CLK_ENABLE();
  __HAL_RCC_GPIOB_CLK_ENABLE();

  /*Configure GPIO pin Output Level */
  HAL_GPIO_WritePin(GPIOC, GPIO_PIN_13, GPIO_PIN_RESET);

  /*Configure GPIO pin Output Level */
  HAL_GPIO_WritePin(GPIOB, GPIO_PIN_0|GPIO_PIN_1|GPIO_PIN_10, GPIO_PIN_RESET);

  /*Configure GPIO pin : PC13 */
  GPIO_InitStruct.Pin = GPIO_PIN_13;
  GPIO_InitStruct.Mode = GPIO_MODE_OUTPUT_PP;
  GPIO_InitStruct.Pull = GPIO_NOPULL;
  GPIO_InitStruct.Speed = GPIO_SPEED_FREQ_LOW;
  HAL_GPIO_Init(GPIOC, &GPIO_InitStruct);

  /*Configure GPIO pins : PB0 PB1 PB10 */
  GPIO_InitStruct.Pin = GPIO_PIN_0|GPIO_PIN_1|GPIO_PIN_10;
  GPIO_InitStruct.Mode = GPIO_MODE_OUTPUT_PP;
  GPIO_InitStruct.Pull = GPIO_NOPULL;
  GPIO_InitStruct.Speed = GPIO_SPEED_FREQ_LOW;
  HAL_GPIO_Init(GPIOB, &GPIO_InitStruct);

  /*Configure GPIO pins : up_Pin down_Pin right_Pin left_Pin
                           draw_stop_Pin */
  GPIO_InitStruct.Pin = up_Pin|down_Pin|right_Pin|left_Pin
                          |draw_stop_Pin;
  GPIO_InitStruct.Mode = GPIO_MODE_INPUT;
  GPIO_InitStruct.Pull = GPIO_PULLDOWN;
  HAL_GPIO_Init(GPIOA, &GPIO_InitStruct);

}

void StartDefaultTask(void const * argument)
{
  /* USER CODE BEGIN 5 */
  /* Infinite loop */
  for(;;)
  {
	HAL_GPIO_TogglePin(GPIOC, GPIO_PIN_13);
	osDelay(500);
  }
  /* USER CODE END 5 */
}

void start_baca_sht(void const * argument)
{
  /* USER CODE BEGIN start_baca_sht */
  /* Infinite loop */
  for(;;)
  {
	temp = SHT2x_GetTemperature(1);
	hum = SHT2x_GetRelativeHumidity(1);
	float sum_temp=0;
	float sum_hum=0;
	// Filter Section for Temp & Hum
	for(int i=0;i<9;i++)
	{
		buffer[i]=buffer[i+1];
		sum_temp=sum_temp+buffer[i];
	}
	buffer[9]=temp;
	sum_temp=sum_temp+buffer[9];
	filtered_temp=sum_temp/10.0;

	for(int i=0;i<9;i++)
	{
		buffer_hum[i]=buffer_hum[i+1];
		sum_hum=sum_hum+buffer_hum[i];
	}
	buffer_hum[9]=hum;
	sum_hum=sum_hum+buffer_hum[9];
	filtered_hum=sum_hum/10.0;
	// End of Filter Section

	snprintf(str1, sizeof(str1), "Temperature = %.2f C", filtered_temp);
	snprintf(str2, sizeof(str2), "R. Humidity = %.2f %%", hum);
    osDelay(500);
  }
  /* USER CODE END start_baca_sht */
}

void start_display(void const * argument)
{
  /* USER CODE BEGIN start_display */
  /* Infinite loop */
  for(;;)
  {

	RTC_DateTypeDef currentDate;
	RTC_TimeTypeDef currentTime;

	HAL_RTC_GetTime(&hrtc, &currentTime, RTC_FORMAT_BIN);
	HAL_RTC_GetDate(&hrtc, &currentDate, RTC_FORMAT_BIN);
	snprintf(date, sizeof(date), "Uptime: %02d:%02d:%02d", currentTime.Hours, currentTime.Minutes, currentTime.Seconds);
	srand(currentTime.Seconds);
	ILI9341_WriteString(0, 50, str1, Font_11x18, 0x663f, ILI9341_BLACK);
	//ILI9341_WriteString(0, 70, str2, Font_11x18, 0x04bf, ILI9341_BLACK); // show humidity
	ILI9341_WriteString(0, 70, date, Font_11x18, ILI9341_WHITE, ILI9341_BLACK); // show time
	ILI9341_WriteString(10, 110, score_left, Font_11x18, 0xff80, ILI9341_BLACK); // show time
	ILI9341_WriteString(270, 110, score_right, Font_11x18, 0x07e2, ILI9341_BLACK); // show time
	/*
	if(isDrawing==true)
	{
		ILI9341_FillRectangle(x,y,3,3,ILI9341_WHITE);
	}
	else
		drawCursor(x,y,oldx,oldy);*/
	updateBallPos(bola.x,bola.y,oldx,oldy);
	updatePaddlePos(user.x,user.y,ouserx,ousery);
	updatePaddlePos(bot.x,bot.y,obotx,oboty);
    osDelay(16);
  }
  /* USER CODE END start_display */
}

void start_input_poll(void const * argument)
{
  /* USER CODE BEGIN start_input_poll */
  /* Infinite loop */
  for(;;)
  {
	  /* sistem untuk gambar
	// arah atas
	if(HAL_GPIO_ReadPin(GPIOA, GPIO_PIN_10) && y-INCREMENT>=108)
	{
		oldy = y;
		y=y-INCREMENT;
	}
	// arah bawah
	else if(HAL_GPIO_ReadPin(GPIOA, GPIO_PIN_9) && y+INCREMENT<=232)
	{
		oldy = y;
		y=y+INCREMENT;
	}
	// kiri
	else if(HAL_GPIO_ReadPin(GPIOA, GPIO_PIN_8) && x-INCREMENT>=8)
	{
		oldx = x;
		x=x-INCREMENT;
	}
	// kanan
	else if(HAL_GPIO_ReadPin(GPIOA, GPIO_PIN_11) && x+INCREMENT<=312)
	{
		oldx = x;
		x=x+INCREMENT;
	}

	if(HAL_GPIO_ReadPin(GPIOA, GPIO_PIN_12) && isDrawing==false)
		isDrawing=true;
	else if(HAL_GPIO_ReadPin(GPIOA, GPIO_PIN_12) && isDrawing==true)
		isDrawing=false;
		*/

	 if(HAL_GPIO_ReadPin(GPIOA, GPIO_PIN_12) && playerEnable==false)
	  	playerEnable=true;
	 else if(HAL_GPIO_ReadPin(GPIOA, GPIO_PIN_12) && playerEnable==true)
	  	playerEnable=false;
	 // paddle user ke atas
	 if(HAL_GPIO_ReadPin(GPIOA, GPIO_PIN_11) && user.y>=110)
	 {
	  	ousery = user.y;
	  	user.y=user.y-user.speed;
	 }
	 // paddle bot ke bawah
	 else if(HAL_GPIO_ReadPin(GPIOA, GPIO_PIN_10) && user.y+user.height<=230)
	 {
		ousery = user.y;
		user.y=user.y+user.speed;
	 }
	 if(HAL_GPIO_ReadPin(GPIOA, GPIO_PIN_9) && bot.y>=110 && playerEnable==true)
	 {
	 	oboty = bot.y;
	 	bot.y=bot.y-bot.speed;
	 }
	 	 // paddle bot ke bawah
	 else if(HAL_GPIO_ReadPin(GPIOA, GPIO_PIN_8) && bot.y+bot.height<=230 && playerEnable==true)
	 {
	 	oboty = bot.y;
	    bot.y=bot.y+bot.speed;
	 }
    osDelay(16);
  }
  /* USER CODE END start_input_poll */
}

void start_game_master(void const * argument)
{
  /* USER CODE BEGIN start_game_master */
  /* Infinite loop */
  for(;;)
  {
	// Crossing Paddle Score
	if(bola.x+2>=user.x+user.width && (bola.y >= user.y+user.height || bola.y <= user.y)){
	  	scoreL=scoreL+1;
	  	snprintf(score_left, sizeof(score_left), "%d", scoreL);
	  	resetBallStatus();
	}
	else if(bola.x<=bot.x && (bola.y >= bot.y+bot.height || bola.y <= bot.y)){
	  	scoreR=scoreR+1;
	  	snprintf(score_right, sizeof(score_right), "%d", scoreR);
	  	resetBallStatus();
	}

	// Reflecting Algorithm
	if(bola.x+2>=user.x && (bola.y >= user.y && bola.y <= user.y+user.height)){
		bola.velx=-bola.velx;
	}
	else if(bola.x<=bot.x+bot.width && (bola.y >= bot.y && bola.y <= bot.y+bot.height)){
		bola.velx=-bola.velx;
	}

	// Reflecting With Top and Bottom Boundary
	if(bola.y<=110){
		bola.vely=-bola.vely;
	}
	else if(bola.y>=229){
		bola.vely=-bola.vely;
	}

	// bot (left paddle) chasing ball's y position
	if((bot.y+bot.height/2 != bola.y+1 && playerEnable == false)/* && (bot.y>=120 || bot.y+bot.height<=240)*/)
	{
		if((bot.y+bot.height/2 < bola.y+1) && bot.y+bot.height<=230)
		{
			oboty=bot.y;
			bot.y=bot.y+bot.speed;
		}
		else if((bot.y+bot.height/2 > bola.y+1) && bot.y>=110)
		{	oboty=bot.y;
			bot.y=bot.y-bot.speed;
		}
	}

	oldx=bola.x;
	oldy=bola.y;
	bola.x=bola.x+bola.velx;
	bola.y=bola.y+bola.vely;
    osDelay(16);
  }
  /* USER CODE END start_game_master */
}

void HAL_TIM_PeriodElapsedCallback(TIM_HandleTypeDef *htim)
{
  if (htim->Instance == TIM1) {
    HAL_IncTick();
  }
}

void Error_Handler(void)
{
  __disable_irq();
  while (1)
  {
  }
}
